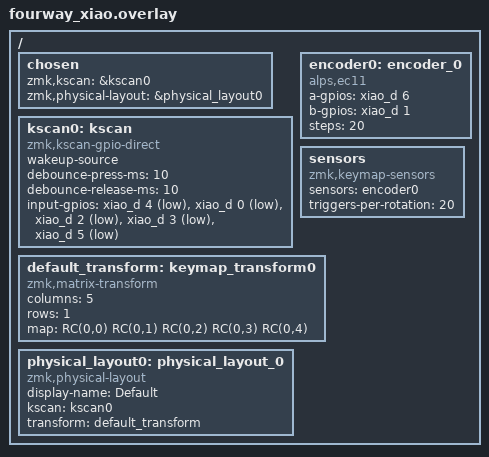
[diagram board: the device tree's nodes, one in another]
#include <dt-bindings/zmk/matrix_transform.h>

/ {
    chosen {
        zmk,kscan = &kscan0;
        zmk,physical-layout = &physical_layout0;
    };

    /*
     * main-board-8 <-> 4way-re-board (RKJXT1F42001), 8-pin:
     *   D3 = D
     *   D6 = Encoder A
     *   D5 = Push
     *   D4 = A
     *   D2 = C
     *   D1 = Encoder B
     *   D0 = B
     *   GND = GND (Com / ECom)
     *
     * kscan order: A, B, C, D, Push
     */
    kscan0: kscan {
        compatible = "zmk,kscan-gpio-direct";
        wakeup-source;
        debounce-press-ms = <10>;
        debounce-release-ms = <10>;
        input-gpios
            = <&xiao_d 4 (GPIO_ACTIVE_LOW | GPIO_PULL_UP)>
            , <&xiao_d 0 (GPIO_ACTIVE_LOW | GPIO_PULL_UP)>
            , <&xiao_d 2 (GPIO_ACTIVE_LOW | GPIO_PULL_UP)>
            , <&xiao_d 3 (GPIO_ACTIVE_LOW | GPIO_PULL_UP)>
            , <&xiao_d 5 (GPIO_ACTIVE_LOW | GPIO_PULL_UP)>
            ;
    };

    encoder0: encoder_0 {
        compatible = "alps,ec11";
        a-gpios = <&xiao_d 6 (GPIO_ACTIVE_HIGH | GPIO_PULL_UP)>;
        b-gpios = <&xiao_d 1 (GPIO_ACTIVE_HIGH | GPIO_PULL_UP)>;
        steps = <20>;
        status = "okay";
    };

    sensors {
        compatible = "zmk,keymap-sensors";
        sensors = <&encoder0>;
        triggers-per-rotation = <20>;
    };

    default_transform: keymap_transform0 {
        compatible = "zmk,matrix-transform";
        columns = <5>;
        rows = <1>;
        map = <
            RC(0,0) RC(0,1) RC(0,2) RC(0,3) RC(0,4)
        >;
    };

    physical_layout0: physical_layout_0 {
        compatible = "zmk,physical-layout";
        display-name = "Default";
        kscan = <&kscan0>;
        transform = <&default_transform>;
    };
};
